# GD32E53x register map
File version: 1.0
CPU: CM33 r0p4, little endian, MPU, FPU, 4 interrupt priority bits
Registers are 32-bit, read-write, reset 0x0 unless marked. A register's access mark holds for its fields unless they carry their own. Offsets are from the block's base; [hi:lo] are bit positions; 'fields as' and 'values as' point back to an identical list.

## CRC — Cyclic redundancy checks management unit
Base 0x40023000
0x00 DATA reset 0xFFFFFFFF
  [31:0] DATA — CRC calculation result bits
0x04 FDATA — Free data register
  [7:0] FDATA — Free data register bits
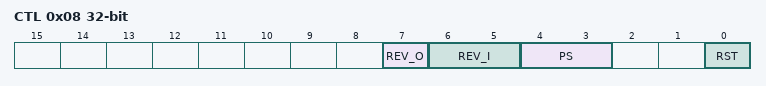
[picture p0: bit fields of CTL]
0x08 CTL — Control register
  [7] REV_O — Reverse output data value in bit order
  [6:5] REV_I — Reverse type for input data
  [4:3] PS — Size of polynomial
  [0] RST — Software writes and reads.
0x10 IDATA reset 0xFFFFFFFF — Initialization data register
  [31:0] IDATA — Configurable initial CRC data value
0x14 POLY reset 0x4C11DB7 — Polynomial register
  [31:0] POLY — User configurable polynomial value

## CTC0 — Clock trim controller
Base 0x4000C800
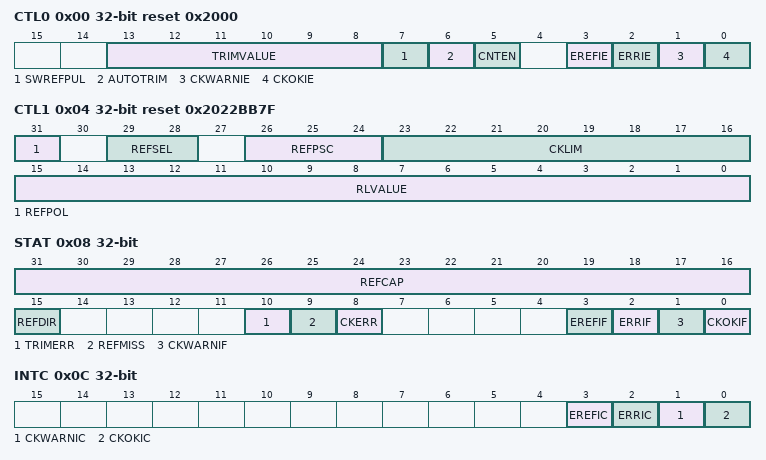
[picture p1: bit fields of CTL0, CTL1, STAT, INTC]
0x00 CTL0 access per field reset 0x2000 — Control register 0
  [13:8] TRIMVALUE rw — IRC48M / IRC8M trim value
  [7] SWREFPUL wo — Software reference source sync pulse
  [6] AUTOTRIM rw — Hardware automatically trim mode
  [5] CNTEN rw — CTC counter enable
  [3] EREFIE rw — EREFIF interrupt enable
  [2] ERRIE rw — Error (ERRIF) interrupt enable
  [1] CKWARNIE rw — Clock trim warning (CKWARNIF) interrupt enable
  [0] CKOKIE rw — Clock trim OK (CKOKIF) interrupt enable
0x04 CTL1 reset 0x2022BB7F — Control register 1
  [31] REFPOL — Reference signal source polarity
  [29:28] REFSEL — Reference signal source selection
  [26:24] REFPSC — Reference signal source prescaler
  [23:16] CKLIM — Clock trim base limit value
  [15:0] RLVALUE — CTC counter reload value
0x08 STAT ro — Status register
  [31:16] REFCAP — CTC counter capture when reference sync pulse.
  [15] REFDIR — CTC trim counter direction when reference sync pulse
  [10] TRIMERR — Trim value error bit
  [9] REFMISS — Reference sync pulse miss
  [8] CKERR — Clock trim error bit
  [3] EREFIF — Expect reference interrupt flag
  [2] ERRIF — Error interrupt flag
  [1] CKWARNIF — Clock trim warning interrupt flag
  [0] CKOKIF — Clock trim OK interrupt flag
0x0C INTC wo — Interrupt clear register
  [3] EREFIC — EREFIF interrupt clear bit
  [2] ERRIC — ERRIF interrupt clear bit
  [1] CKWARNIC — CKWARNIF interrupt clear bit
  [0] CKOKIC — CKOKIF interrupt clear bit

## CTC1 — Clock trim controller
Base 0x4000CC00
Registers as CTC0; these are added or differ:
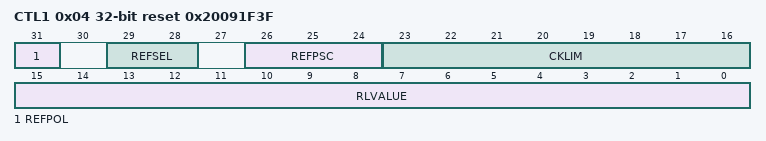
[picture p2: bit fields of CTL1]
0x04 CTL1 reset 0x20091F3F — Control register 1
  fields as CTC0.CTL1

## DAC0 — Digital-to-analog converter
Base 0x40007400
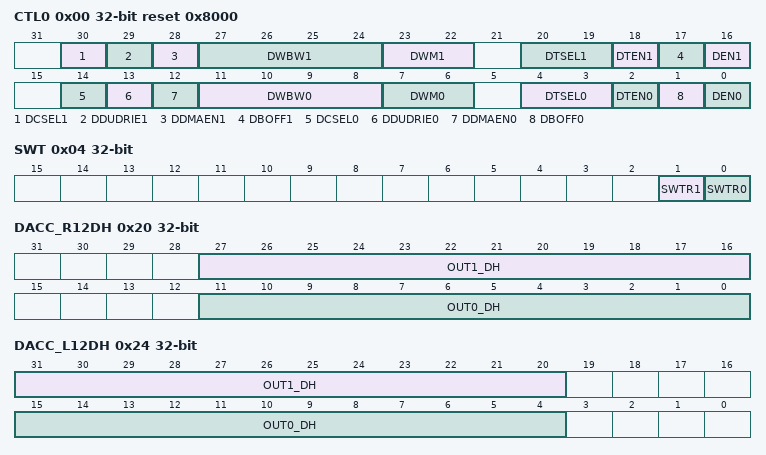
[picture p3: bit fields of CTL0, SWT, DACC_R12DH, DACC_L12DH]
0x00 CTL0 reset 0x8000 — DACx control register 0
  [30] DCSEL1 — Connection selection of DACx_OUT1 with GPIO
  [29] DDUDRIE1 — DACx_OUT1 DMA underrun interrupt enable
  [28] DDMAEN1 — DACx_OUT1 DMA enable
  [27:24] DWBW1 — DACx_OUT1 noise wave bit width
  [23:22] DWM1 — DACx_OUT1 noise wave mode
  [20:19] DTSEL1 — DACx_OUT1 trigger selection
  [18] DTEN1 — DACx_OUT1 trigger enable
  [17] DBOFF1 — DACx_OUT1 output buffer turn off
  [16] DEN1 — DACx_OUT1 enable
  [14] DCSEL0 — Connection selection of DACx_OUT0 with GPIO:
  [13] DDUDRIE0 — DACx_OUT0 DMA underrun interrupt enable
  [12] DDMAEN0 — DACx_OUT0 DMA enable
  [11:8] DWBW0 — DACx_OUT0 noise wave bit width
  [7:6] DWM0 — DACx_OUT0 noise wave mode
  [4:3] DTSEL0 — DACx_OUT0 trigger selection
  [2] DTEN0 — DACx_OUT0 trigger enable
  [1] DBOFF0 — DACx_OUT0 output buffer turn off
  [0] DEN0 — DACx_OUT0 enable
0x04 SWT wo — DACx software trigger register
  [1] SWTR1 — DACx_OUT1 software trigger, cleared by hardware.
  [0] SWTR0 — DACx_OUT0 software trigger, cleared by hardware.
0x08 OUT0_R12DH — DACx_OUT0 12-bit right-aligned data holding register
  [11:0] OUT0_DH — DACx_OUT0 12-bit right-aligned data.
0x0C OUT0_L12DH — DACx_OUT0 12-bit left-aligned data holding register
  [15:4] OUT0_DH — DACx_OUT0 12-bit left-aligned data.
0x10 OUT0_R8DH — DACx_OUT0 8-bit right-aligned data holding register
  [7:0] OUT0_DH — DACx_OUT0 8-bit right-aligned data.
0x14 OUT1_R12DH — DACx_OUT1 12-bit right-aligned data holding register
  [11:0] OUT1_DH — DACx_OUT1 12-bit right-aligned data.
0x18 OUT1_L12DH — DACx_OUT1 12-bit left-aligned data holding register
  [15:4] OUT1_DH — DACx_OUT1 12-bit left-aligned data.
0x1C OUT1_R8DH — DACx_OUT1 8-bit right-aligned data holding register
  [7:0] OUT1_DH — DACx_OUT1 8-bit right-aligned data.
0x20 DACC_R12DH ro — DACx concurrent mode 12-bit right-aligned data holding register
  [27:16] OUT1_DH — DACx_OUT1 12-bit right-aligned data
  [11:0] OUT0_DH — DACx_OUT0 12-bit right-aligned data
0x24 DACC_L12DH ro — DACx concurrent mode 12-bit left-aligned data holding register
  [31:20] OUT1_DH — DACx_OUT1 12-bit left-aligned data
  [15:4] OUT0_DH — DACx_OUT0 12-bit left-aligned data
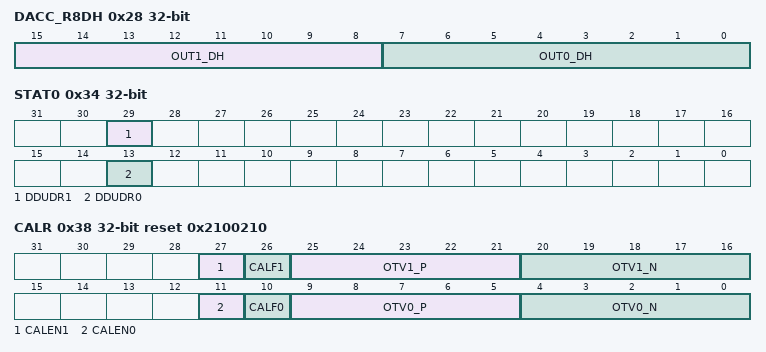
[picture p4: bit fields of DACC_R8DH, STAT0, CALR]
0x28 DACC_R8DH — DACx concurrent mode 8-bit right-aligned data holding register
  [15:8] OUT1_DH — DACx_OUT1 8-bit right-aligned data
  [7:0] OUT0_DH — DACx_OUT0 8-bit right-aligned data
0x2C OUT0_DO ro — DACx_OUT0 data output register
  [11:0] OUT0_DO — DACx_OUT0 12-bit output data
0x30 OUT1_DO ro — DACx_OUT1 data output register
  [11:0] OUT1_DO — DACx_OUT1 12-bit output data
0x34 STAT0 — DACx_OUT0 status register 0
  [29] DDUDR1 — DACx_OUT1 DMA underrun flag.
  [13] DDUDR0 — DACx_OUT0 DMA underrun flag.
0x38 CALR access per field reset 0x2100210 — DACx calibration register
  [27] CALEN1 rw — DACx_OUT1 calibration enable
  [26] CALF1 ro — DACx_OUT1 calibration offset flag.
  [25:21] OTV1_P rw — DACx_OUT1 offset calibration value P.
  [20:16] OTV1_N rw — DACx_OUT1 offset calibration value N.
  [11] CALEN0 rw — DACx_OUT0 calibration enable
  [10] CALF0 ro — DACx_OUT0 calibration offset flag.
  [9:5] OTV0_P rw — DACx_OUT0 offset calibration value P.
  [4:0] OTV0_N rw — DACx_OUT0 offset calibration value N.
